# PIC32MZ2051W104132 register map
Vendor: Microchip
Registers are 32-bit, read-write, no defined reset value unless marked. A register's access mark holds for its fields unless they carry their own. Addresses are absolute, and some are shared; only a register's first bit layout is shown; [hi:lo] are bit positions; {n}, {i} and the like mark numbered series.

## SFR
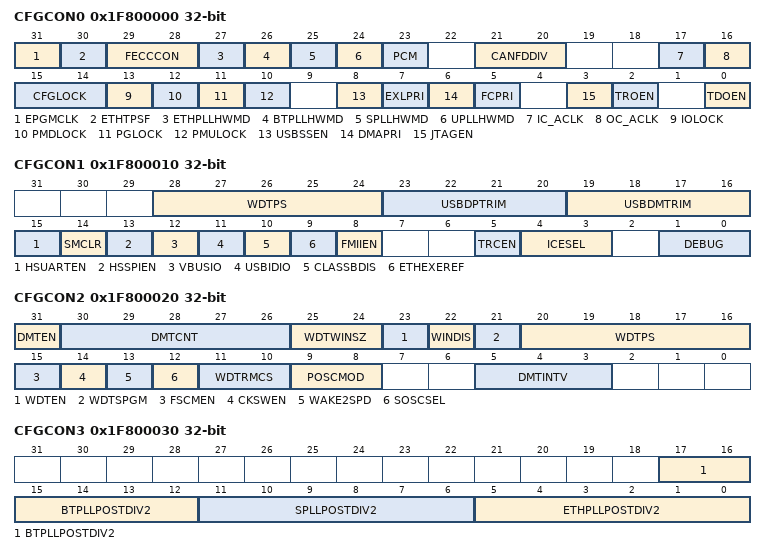
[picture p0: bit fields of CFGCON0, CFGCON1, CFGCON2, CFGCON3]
0x1F800000 CFGCON0 — (power-on value qqqqqqqqq-qq--qqqqqqqq-qqqq-qq-q)
  [31] EPGMCLK
  [30] ETHTPSF
  [29:28] FECCCON
  [27] ETHPLLHWMD
  [26] BTPLLHWMD
  [25] SPLLHWMD
  [24] UPLLHWMD
  [23] PCM
  [21:20] CANFDDIV — CAN-FD divider control
  [17] IC_ACLK
  [16] OC_ACLK
  [15:14] CFGLOCK
  [13] IOLOCK
  [12] PMDLOCK
  [11] PGLOCK
  [10] PMULOCK
  [8] USBSSEN
  [7] EXLPRI
  [6] DMAPRI
  [5] FCPRI
  [3] JTAGEN — JTAG control bit
  [2] TROEN — Trace clock control bit
  [0] TDOEN — TDO control for 2 wire JTAG protocol
0x1F800010 CFGCON1 — (power-on value ---qqqqqqqqqqqqqqqqqqqqq--qqq-qq)
  [28:24] WDTPS, [23:20] USBDPTRIM, [19:16] USBDMTRIM, [15] HSUARTEN, [14] SMCLR, [13] HSSPIEN, [12] VBUSIO, [11] USBIDIO, [10] CLASSBDIS, [9] ETHEXEREF, [8] FMIIEN, [5] TRCEN, [4:3] ICESEL, [1:0] DEBUG
0x1F800020 CFGCON2 — (power-on value qqqqqqqqqqqqqqqqqqqqqqqq--qqq---)
  [31] DMTEN, [30:26] DMTCNT, [25:24] WDTWINSZ, [23] WDTEN, [22] WINDIS, [21] WDTSPGM, [20:16] WDTPS, [15] FSCMEN, [14] CKSWEN, [13] WAKE2SPD, [12] SOSCSEL, [11:10] WDTRMCS, [9:8] POSCMOD, [5:3] DMTINTV
0x1F800030 CFGCON3 — (power-on value --------------qqqqqqqqqqqqqqqqqq)
  [17:12] BTPLLPOSTDIV2, [11:6] SPLLPOSTDIV2, [5:0] ETHPLLPOSTDIV2
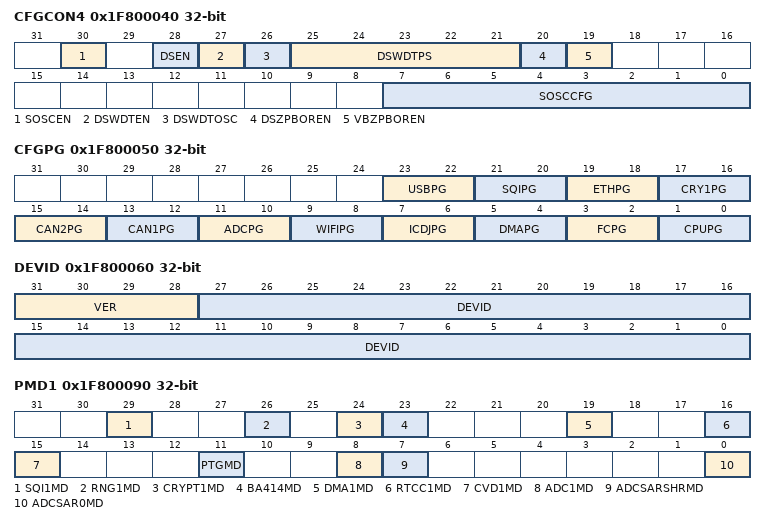
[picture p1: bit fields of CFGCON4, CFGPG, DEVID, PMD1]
0x1F800040 CFGCON4 — (power-on value -q-qqqqqqqqqq-----------qqqqqqqq)
  [30] SOSCEN, [28] DSEN, [27] DSWDTEN, [26] DSWDTOSC, [25:21] DSWDTPS, [20] DSZPBOREN, [19] VBZPBOREN, [7:0] SOSCCFG
0x1F800050 CFGPG — (power-on value --------qqqqqqqqqqqqqqqqqqqqqqqq)
  [23:22] USBPG, [21:20] SQIPG, [19:18] ETHPG, [17:16] CRY1PG, [15:14] CAN2PG, [13:12] CAN1PG, [11:10] ADCPG, [9:8] WIFIPG, [7:6] ICDJPG, [5:4] DMAPG, [3:2] FCPG, [1:0] CPUPG
0x1F800060 DEVID ro — (power-on value qqqqqqqqqqqqqqqqqqqqqqqqqqqqqqqq)
  [31:28] VER, [27:0] DEVID
0x1F800070 USERID — (power-on value ----------------xxxxxxxxxxxxxxxx)
  [15:0] USERID
0x1F800080 SYSKEY — (power-on value xxxxxxxxxxxxxxxxxxxxxxxxxxxxxxxx)
0x1F800090 PMD1 — (power-on value --x--x-xx---x--xx---x--xx------x)
  [29] SQI1MD, [26] RNG1MD, [24] CRYPT1MD, [23] BA414MD, [19] DMA1MD, [16] RTCC1MD, [15] CVD1MD, [11] PTGMD, [8] ADC1MD, [7] ADCSARSHRMD, [0] ADCSAR0MD
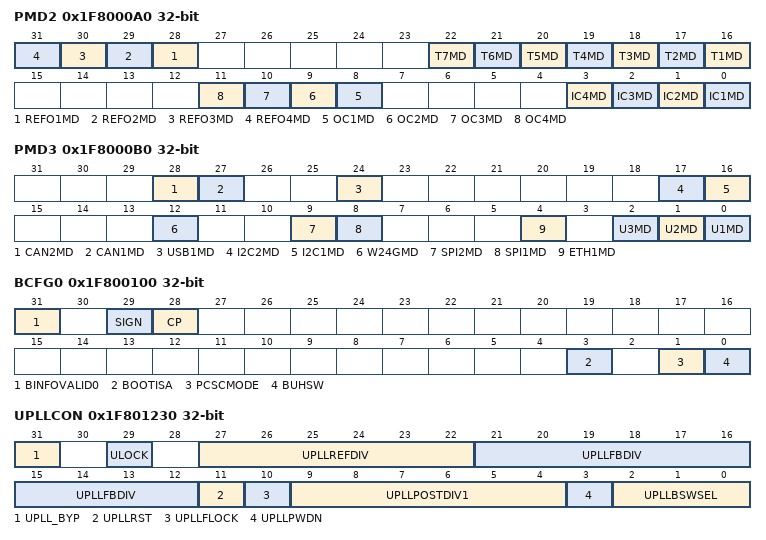
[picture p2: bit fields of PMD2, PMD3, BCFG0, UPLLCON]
0x1F8000A0 PMD2 — (power-on value xxxx-----xxxxxxx----xxxx----xxxx)
  [n+27] REFO{n}MD (n=1..4), [n+15] T{n}MD (n=1..7), [n+7] OC{n}MD (n=1..4), [n-1] IC{n}MD (n=1..4)
0x1F8000B0 PMD3 — (power-on value ---xx--x------xx---x--xx---x-xxx)
  [28] CAN2MD, [27] CAN1MD, [24] USB1MD, [17] I2C2MD, [16] I2C1MD, [12] W24GMD, [9] SPI2MD, [8] SPI1MD, [4] ETH1MD, [2] U3MD, [1] U2MD, [0] U1MD
0x1F800100 BCFG0 ro — (power-on value q-qq------------------------q-qq)
  [31] BINFOVALID0, [29] SIGN, [28] CP, [3] BOOTISA, [1] PCSCMODE, [0] BUHSW
0x1F801230 UPLLCON — (power-on value x-x-xxxxxxxxxxxxxxxxxxxxxxxxxxxx)
  [31] UPLL_BYP, [29] ULOCK, [27:22] UPLLREFDIV, [21:12] UPLLFBDIV, [11] UPLLRST, [10] UPLLFLOCK, [9:4] UPLLPOSTDIV1, [3] UPLLPWDN, [2:0] UPLLBSWSEL
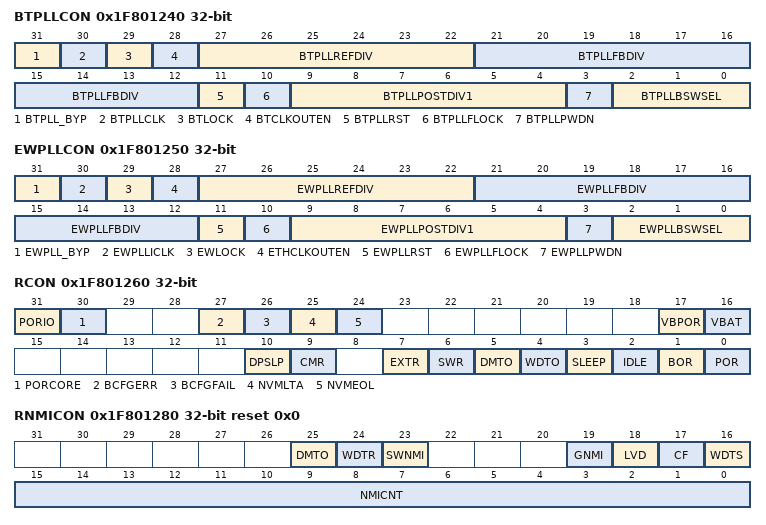
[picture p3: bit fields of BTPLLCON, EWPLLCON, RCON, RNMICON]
0x1F801240 BTPLLCON — (power-on value xxxxxxxxxxxxxxxxxxxxxxxxxxxxxxxx)
  [31] BTPLL_BYP, [30] BTPLLCLK, [29] BTLOCK, [28] BTCLKOUTEN, [27:22] BTPLLREFDIV, [21:12] BTPLLFBDIV, [11] BTPLLRST, [10] BTPLLFLOCK, [9:4] BTPLLPOSTDIV1, [3] BTPLLPWDN, [2:0] BTPLLBSWSEL
0x1F801250 EWPLLCON — (power-on value xxxxxxxxxxxxxxxxxxxxxxxxxxxxxxxx)
  [31] EWPLL_BYP, [30] EWPLLICLK, [29] EWLOCK, [28] ETHCLKOUTEN, [27:22] EWPLLREFDIV, [21:12] EWPLLFBDIV, [11] EWPLLRST, [10] EWPLLFLOCK, [9:4] EWPLLPOSTDIV1, [3] EWPLLPWDN, [2:0] EWPLLBSWSEL
0x1F801260 RCON — (power-on value 00--00x0-------------x0-00000011)
  [31] PORIO, [30] PORCORE, [27] BCFGERR, [26] BCFGFAIL, [25] NVMLTA, [24] NVMEOL, [17] VBPOR, [16] VBAT, [10] DPSLP, [9] CMR, [7] EXTR, [6] SWR, [5] DMTO, [4] WDTO, [3] SLEEP, [2] IDLE, [1] BOR, [0] POR
0x1F801270 RSWRST wo reset 0x0
  [0] SWRST
0x1F801280 RNMICON reset 0x0
  [25] DMTO, [24] WDTR, [23] SWNMI, [19] GNMI, [18] LVD, [17] CF, [16] WDTS, [15:0] NMICNT
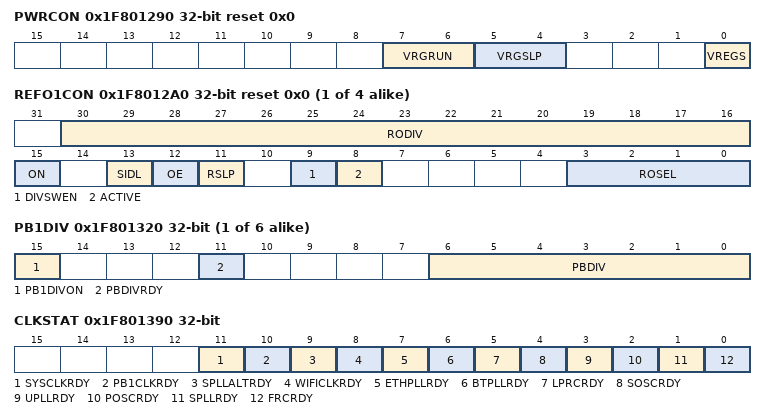
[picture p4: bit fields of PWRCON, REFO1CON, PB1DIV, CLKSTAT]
0x1F801290 PWRCON reset 0x0
  [7:6] VRGRUN, [5:4] VRGSLP, [0] VREGS
{0x1F801280+0x20*i} REFO{i}CON reset 0x0 (i=1..4)
  [30:16] RODIV, [15] ON, [13] SIDL, [12] OE, [11] RSLP, [9] DIVSWEN, [8] ACTIVE ro, [3:0] ROSEL
{0x1F801290+0x20*i} REFO{i}TRIM reset 0x0 (i=1..4)
  [31:23] ROTRIM
{0x1F801310+0x10*i} PB{i}DIV (i=1..6) — (power-on value ----------------1---1----xxxxxxx)
  [15] PB{i}DIVON, [11] PBDIVRDY ro, [6:0] PBDIV
0x1F801390 CLKSTAT — (power-on value --------------------xxxx0x0000x0)
  [11] SYSCLKRDY, [10] PB1CLKRDY, [9] SPLLALTRDY, [8] WIFICLKRDY, [7] ETHPLLRDY ro, [6] BTPLLRDY, [5] LPRCRDY ro, [4] SOSCRDY ro, [3] UPLLRDY ro, [2] POSCRDY ro, [1] SPLLRDY, [0] FRCRDY ro
0x1F8013A0 OSCCONBAR access not given
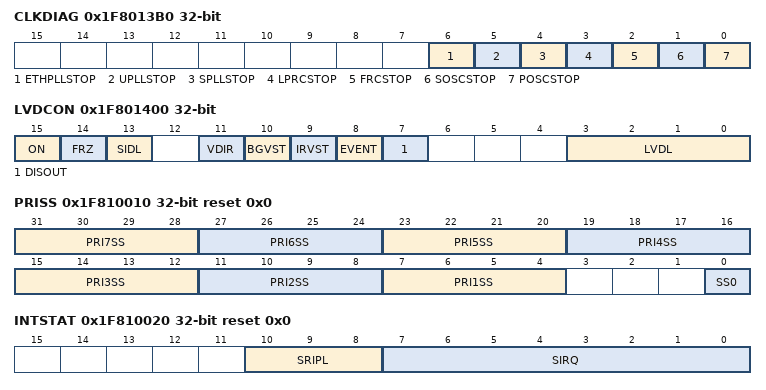
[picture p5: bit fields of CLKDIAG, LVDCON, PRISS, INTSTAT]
0x1F8013B0 CLKDIAG — (power-on value -------------------------xxxxxxx)
  [6] ETHPLLSTOP, [5] UPLLSTOP, [4] SPLLSTOP, [3] LPRCSTOP, [2] FRCSTOP, [1] SOSCSTOP, [0] POSCSTOP
0x1F801400 LVDCON — (power-on value ----------------xxx-xxxxx---xxxx)
  [15] ON, [14] FRZ, [13] SIDL, [11] VDIR, [10] BGVST, [9] IRVST, [8] EVENT, [7] DISOUT, [3:0] LVDL
{0x1F801800+4i} INT{i}R (i=0..4) — (power-on value ----------------------------xxxx)
  [3:0] INT{i}R
{0x1F801810+4i} T{i}CKR (i=1..7) — (power-on value ----------------------------xxxx)
  [3:0] T{i}CKR
{0x1F801834+4i} IC{i}R (i=1..4) — (power-on value ----------------------------xxxx)
  [3:0] IC{i}R
0x1F80185C OCFAR — (power-on value ----------------------------xxxx)
  [3:0] OCFAR
0x1F801860 OCFBR — (power-on value ----------------------------xxxx)
  [3:0] OCFBR
0x1F801864 OCFCR — (power-on value ----------------------------xxxx)
  [3:0] OCFCR
0x1F801868 OCFDR — (power-on value ----------------------------xxxx)
  [3:0] OCFDR
{0x1F801864+8i} U{i}RXR (i=1..3) — (power-on value ----------------------------xxxx)
  [3:0] U{i}RXR
{0x1F801868+8i} U{i}CTSR (i=1..3) — (power-on value ----------------------------xxxx)
  [3:0] U{i}CTSR
0x1F80188C PTG30R — (power-on value ----------------------------xxxx)
  [3:0] PTG30R
0x1F801890 PTG31R — (power-on value ----------------------------xxxx)
  [3:0] PTG31R
0x1F801898 SDI1R — (power-on value ----------------------------xxxx)
  [3:0] SDI1R
0x1F80189C SS1INR — (power-on value ----------------------------xxxx)
  [3:0] SS1INR
0x1F8018A4 SDI2R — (power-on value ----------------------------xxxx)
  [3:0] SDI2R
0x1F8018A8 SS2INR — (power-on value ----------------------------xxxx)
  [3:0] SS2INR
0x1F8018C4 C1RXR — (power-on value ----------------------------xxxx)
  [3:0] C1RXR
0x1F8018C8 C2RXR — (power-on value ----------------------------xxxx)
  [3:0] C2RXR
0x1F8018CC REFIR — (power-on value ----------------------------xxxx)
  [3:0] REFIR
0x1F801974 ECOLR — (power-on value ----------------------------xxxx)
  [3:0] ECOLR
0x1F801978 ECRSR — (power-on value ----------------------------xxxx)
  [3:0] ECRSR
0x1F80197C ETXCLKR — (power-on value ----------------------------xxxx)
  [3:0] ETXCLKR
0x1F801980 ERXD3R — (power-on value ----------------------------xxxx)
  [3:0] ERXD3R
0x1F801984 ERXD2R — (power-on value ----------------------------xxxx)
  [3:0] ERXD2R
{0x1F801A00+4i} RPA{i}R (i=0..5) — (power-on value ---------------------------xxxxx)
  [4:0] RPA{i}R
{0x1F801A00+4i} RPA{i}R (i=10..15) — (power-on value ---------------------------xxxxx)
  [4:0] RPA{i}R
{0x1F801A40+4i} RPB{i}R (i=0..14) — (power-on value ---------------------------xxxxx)
  [4:0] RPB{i}R
{0x1F801A80+4i} RPC{i}R (i=0..15) — (power-on value ---------------------------xxxxx)
  [4:0] RPC{i}R
{0x1F801AC0+4i} RPK{i}R (i=0..14) — (power-on value ---------------------------xxxxx)
  [4:0] RPK{i}R
0x1F810010 PRISS reset 0x0
  [4n+3:4n] PRI{n}SS (n=1..7), [0] SS0
0x1F810020 INTSTAT ro reset 0x0
  [10:8] SRIPL, [7:0] SIRQ
0x1F810030 IPTMR reset 0x0
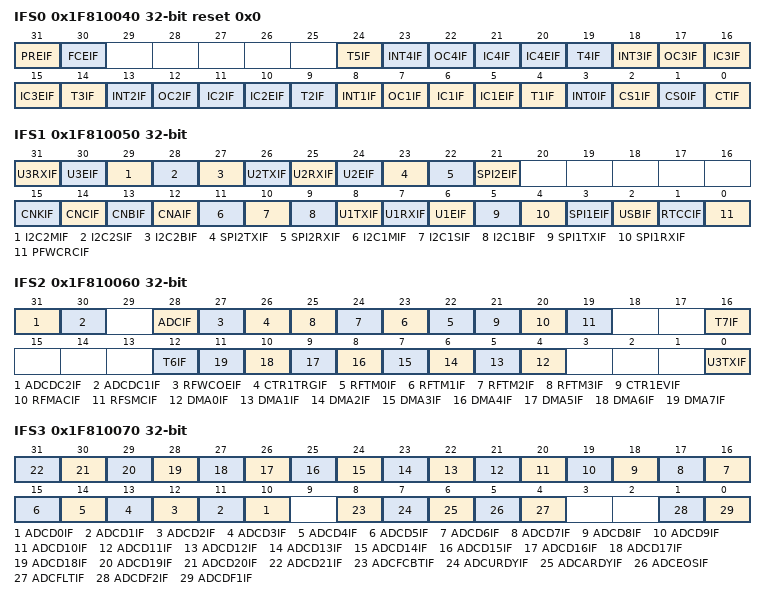
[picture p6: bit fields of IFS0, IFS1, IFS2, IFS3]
0x1F810040 IFS0 reset 0x0
  [31] PREIF, [30] FCEIF, [5n-1] T{n}IF (n=1..5), [5n+3] INT{n}IF (n=0..4), [5n+2] OC{n}IF (n=1..4), [5n+1] IC{n}IF (n=1..4), [5n] IC{n}EIF (n=1..4), [2] CS1IF, [1] CS0IF, [0] CTIF
0x1F810050 IFS1 — (power-on value xx000000000-----00000000000000x0)
  [31] U3RXIF, [30] U3EIF, [29] I2C2MIF, [28] I2C2SIF, [27] I2C2BIF, [26] U2TXIF, [25] U2RXIF, [24] U2EIF, [23] SPI2TXIF, [22] SPI2RXIF, [21] SPI2EIF, [15] CNKIF, [14] CNCIF, [13] CNBIF, [12] CNAIF, [11] I2C1MIF, [10] I2C1SIF, [9] I2C1BIF, [8] U1TXIF, [7] U1RXIF, [6] U1EIF, [5] SPI1TXIF, [4] SPI1RXIF, [3] SPI1EIF, [2] USBIF, [1] RTCCIF, [0] PFWCRCIF
0x1F810060 IFS2 — (power-on value 000000000000x000---000000000---x)
  [31] ADCDC2IF, [30] ADCDC1IF, [28] ADCIF, [27] RFWCOEIF, [26] CTR1TRGIF, [n+22] RFTM{n}IF (n=0..3), [21] CTR1EVIF, [20] RFMACIF, [19] RFSMCIF, [16] T7IF, [12] T6IF, [n+4] DMA{n}IF (n=0..7), [0] U3TXIF
0x1F810070 IFS3 — (power-on value xx00000000000000000-000000000000)
  [n+10] ADCD{n}IF (n=0..21), [8] ADCFCBTIF, [7] ADCURDYIF, [6] ADCARDYIF, [5] ADCEOSIF, [4] ADCFLTIF, [1] ADCDF2IF, [0] ADCDF1IF
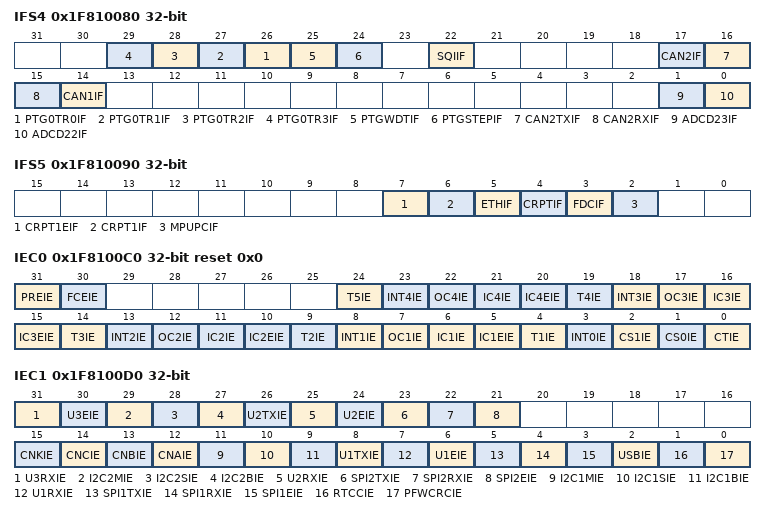
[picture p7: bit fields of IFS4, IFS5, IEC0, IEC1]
0x1F810080 IFS4 — (power-on value 00000000000000xxx0000000000000xx)
  [n+26] PTG0TR{n}IF (n=0..3), [25] PTGWDTIF, [24] PTGSTEPIF, [22] SQIIF, [17] CAN2IF, [16] CAN2TXIF, [15] CAN2RXIF, [14] CAN1IF, [1] ADCD23IF, [0] ADCD22IF
0x1F810090 IFS5 — (power-on value -00000000000000000000000xxxx0000)
  [7] CRPT1EIF, [6] CRPT1IF, [5] ETHIF, [4] CRPTIF, [3] FDCIF, [2] MPUPCIF
0x1F8100C0 IEC0 reset 0x0
  [31] PREIE, [30] FCEIE, [5n-1] T{n}IE (n=1..5), [5n+3] INT{n}IE (n=0..4), [5n+2] OC{n}IE (n=1..4), [5n+1] IC{n}IE (n=1..4), [5n] IC{n}EIE (n=1..4), [2] CS1IE, [1] CS0IE, [0] CTIE
0x1F8100D0 IEC1 — (power-on value xx000x000000000000000000000000x0)
  [31] U3RXIE, [30] U3EIE, [29] I2C2MIE, [28] I2C2SIE, [27] I2C2BIE, [26] U2TXIE, [25] U2RXIE, [24] U2EIE, [23] SPI2TXIE, [22] SPI2RXIE, [21] SPI2EIE, [15] CNKIE, [14] CNCIE, [13] CNBIE, [12] CNAIE, [11] I2C1MIE, [10] I2C1SIE, [9] I2C1BIE, [8] U1TXIE, [7] U1RXIE, [6] U1EIE, [5] SPI1TXIE, [4] SPI1RXIE, [3] SPI1EIE, [2] USBIE, [1] RTCCIE, [0] PFWCRCIE
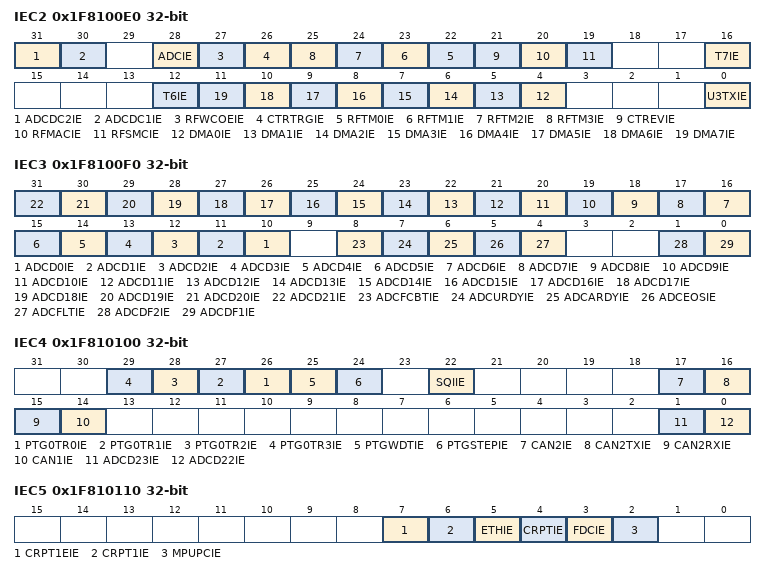
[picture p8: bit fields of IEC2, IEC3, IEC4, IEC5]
0x1F8100E0 IEC2 — (power-on value 000000000000x000000000000000000x)
  [31] ADCDC2IE, [30] ADCDC1IE, [28] ADCIE, [27] RFWCOEIE, [26] CTRTRGIE, [n+22] RFTM{n}IE (n=0..3), [21] CTREVIE, [20] RFMACIE, [19] RFSMCIE, [16] T7IE, [12] T6IE, [n+4] DMA{n}IE (n=0..7), [0] U3TXIE
0x1F8100F0 IEC3 — (power-on value xx00000000000000000-000000000000)
  [n+10] ADCD{n}IE (n=0..21), [8] ADCFCBTIE, [7] ADCURDYIE, [6] ADCARDYIE, [5] ADCEOSIE, [4] ADCFLTIE, [1] ADCDF2IE, [0] ADCDF1IE
0x1F810100 IEC4 — (power-on value 00000000000000xxx0000000000000xx)
  [n+26] PTG0TR{n}IE (n=0..3), [25] PTGWDTIE, [24] PTGSTEPIE, [22] SQIIE, [17] CAN2IE, [16] CAN2TXIE, [15] CAN2RXIE, [14] CAN1IE, [1] ADCD23IE, [0] ADCD22IE
0x1F810110 IEC5 — (power-on value -00000000000000000000000xxxx0000)
  [7] CRPT1EIE, [6] CRPT1IE, [5] ETHIE, [4] CRPTIE, [3] FDCIE, [2] MPUPCIE
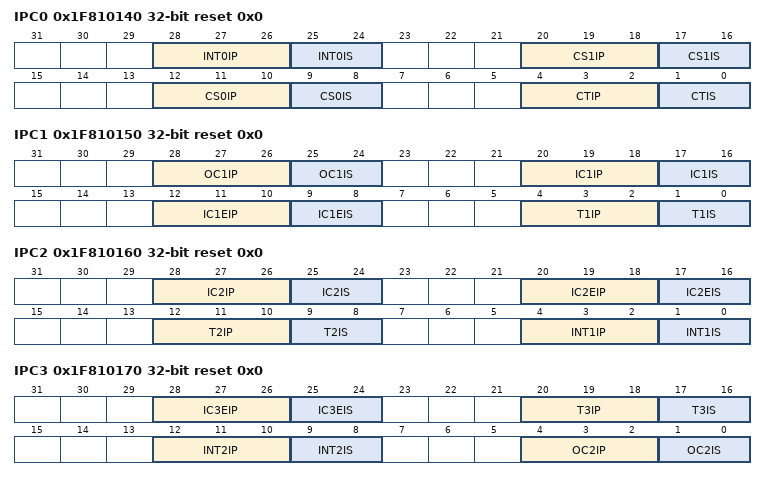
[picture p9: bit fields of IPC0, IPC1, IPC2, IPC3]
0x1F810140 IPC0 reset 0x0
  [28:26] INT0IP, [25:24] INT0IS, [20:18] CS1IP, [17:16] CS1IS, [12:10] CS0IP, [9:8] CS0IS, [4:2] CTIP, [1:0] CTIS
0x1F810150 IPC1 reset 0x0
  [28:26] OC1IP, [25:24] OC1IS, [20:18] IC1IP, [17:16] IC1IS, [12:10] IC1EIP, [9:8] IC1EIS, [4:2] T1IP, [1:0] T1IS
0x1F810160 IPC2 reset 0x0
  [28:26] IC2IP, [25:24] IC2IS, [20:18] IC2EIP, [17:16] IC2EIS, [12:10] T2IP, [9:8] T2IS, [4:2] INT1IP, [1:0] INT1IS
0x1F810170 IPC3 reset 0x0
  [28:26] IC3EIP, [25:24] IC3EIS, [20:18] T3IP, [17:16] T3IS, [12:10] INT2IP, [9:8] INT2IS, [4:2] OC2IP, [1:0] OC2IS
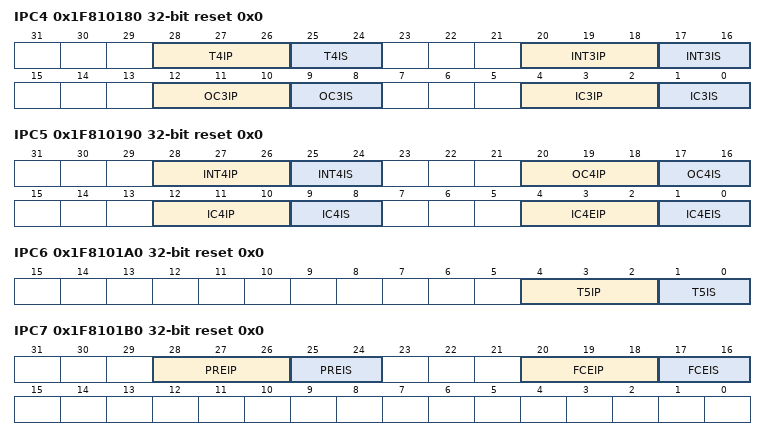
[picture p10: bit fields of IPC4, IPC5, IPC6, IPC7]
0x1F810180 IPC4 reset 0x0
  [28:26] T4IP, [25:24] T4IS, [20:18] INT3IP, [17:16] INT3IS, [12:10] OC3IP, [9:8] OC3IS, [4:2] IC3IP, [1:0] IC3IS
0x1F810190 IPC5 reset 0x0
  [28:26] INT4IP, [25:24] INT4IS, [20:18] OC4IP, [17:16] OC4IS, [12:10] IC4IP, [9:8] IC4IS, [4:2] IC4EIP, [1:0] IC4EIS
0x1F8101A0 IPC6 reset 0x0
  [4:2] T5IP, [1:0] T5IS
0x1F8101B0 IPC7 reset 0x0
  [28:26] PREIP, [25:24] PREIS, [20:18] FCEIP, [17:16] FCEIS
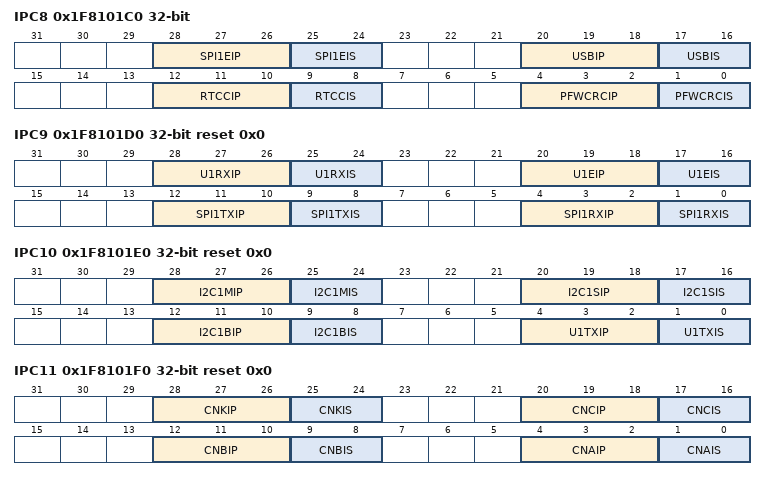
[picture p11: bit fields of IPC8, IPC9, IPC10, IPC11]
0x1F8101C0 IPC8 — (power-on value ---00000---00000---00000---xxxxx)
  [28:26] SPI1EIP, [25:24] SPI1EIS, [20:18] USBIP, [17:16] USBIS, [12:10] RTCCIP, [9:8] RTCCIS, [4:2] PFWCRCIP, [1:0] PFWCRCIS
0x1F8101D0 IPC9 reset 0x0
  [28:26] U1RXIP, [25:24] U1RXIS, [20:18] U1EIP, [17:16] U1EIS, [12:10] SPI1TXIP, [9:8] SPI1TXIS, [4:2] SPI1RXIP, [1:0] SPI1RXIS
0x1F8101E0 IPC10 reset 0x0
  [28:26] I2C1MIP, [25:24] I2C1MIS, [20:18] I2C1SIP, [17:16] I2C1SIS, [12:10] I2C1BIP, [9:8] I2C1BIS, [4:2] U1TXIP, [1:0] U1TXIS
0x1F8101F0 IPC11 reset 0x0
  [28:26] CNKIP, [25:24] CNKIS, [20:18] CNCIP, [17:16] CNCIS, [12:10] CNBIP, [9:8] CNBIS, [4:2] CNAIP, [1:0] CNAIS
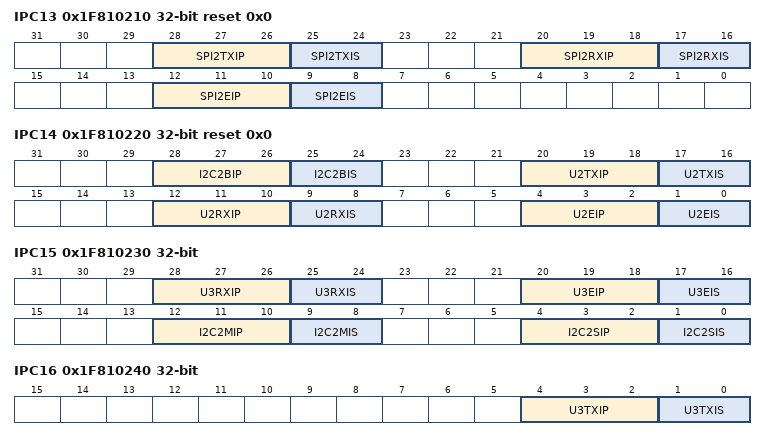
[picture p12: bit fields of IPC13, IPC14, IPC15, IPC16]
0x1F810210 IPC13 reset 0x0
  [28:26] SPI2TXIP, [25:24] SPI2TXIS, [20:18] SPI2RXIP, [17:16] SPI2RXIS, [12:10] SPI2EIP, [9:8] SPI2EIS
0x1F810220 IPC14 reset 0x0
  [28:26] I2C2BIP, [25:24] I2C2BIS, [20:18] U2TXIP, [17:16] U2TXIS, [12:10] U2RXIP, [9:8] U2RXIS, [4:2] U2EIP, [1:0] U2EIS
0x1F810230 IPC15 — (power-on value ---xxxxx---xxxxx---00000---00000)
  [28:26] U3RXIP, [25:24] U3RXIS, [20:18] U3EIP, [17:16] U3EIS, [12:10] I2C2MIP, [9:8] I2C2MIS, [4:2] I2C2SIP, [1:0] I2C2SIS
0x1F810240 IPC16 — (power-on value ---------------------------xxxxx)
  [4:2] U3TXIP, [1:0] U3TXIS
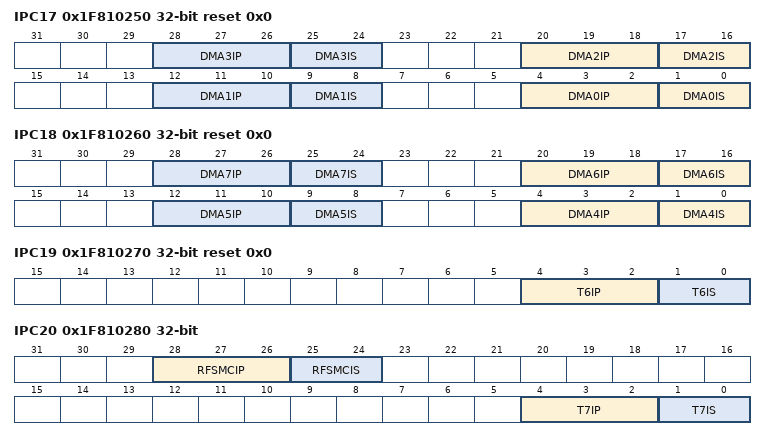
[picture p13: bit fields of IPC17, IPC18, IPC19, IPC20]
0x1F810250 IPC17 reset 0x0
  [8n+4:8n+2] DMA{n}IP (n=0..3), [8n+1:8n] DMA{n}IS (n=0..3)
0x1F810260 IPC18 reset 0x0
  [8n-28:8n-30] DMA{n}IP (n=4..7), [8n-31:8n-32] DMA{n}IS (n=4..7)
0x1F810270 IPC19 reset 0x0
  [4:2] T6IP, [1:0] T6IS
0x1F810280 IPC20 — (power-on value ---xxxxx-------------------00000)
  [28:26] RFSMCIP, [25:24] RFSMCIS, [4:2] T7IP, [1:0] T7IS
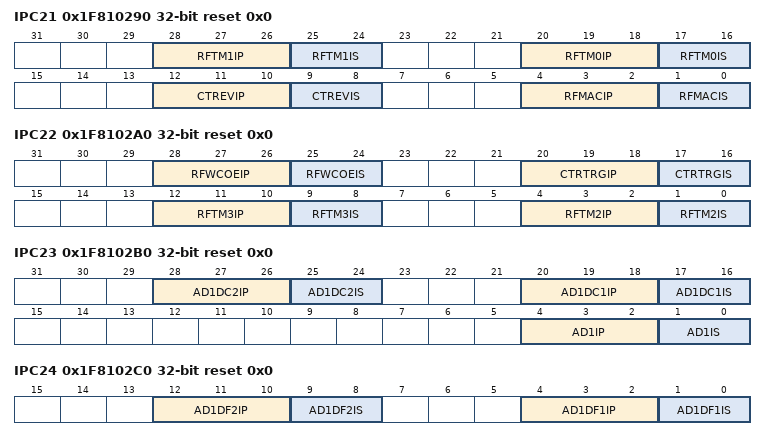
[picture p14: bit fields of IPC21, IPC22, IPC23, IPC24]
0x1F810290 IPC21 reset 0x0
  [28:26] RFTM1IP, [25:24] RFTM1IS, [20:18] RFTM0IP, [17:16] RFTM0IS, [12:10] CTREVIP, [9:8] CTREVIS, [4:2] RFMACIP, [1:0] RFMACIS
0x1F8102A0 IPC22 reset 0x0
  [28:26] RFWCOEIP, [25:24] RFWCOEIS, [20:18] CTRTRGIP, [17:16] CTRTRGIS, [12:10] RFTM3IP, [9:8] RFTM3IS, [4:2] RFTM2IP, [1:0] RFTM2IS
0x1F8102B0 IPC23 reset 0x0
  [28:26] AD1DC2IP, [25:24] AD1DC2IS, [20:18] AD1DC1IP, [17:16] AD1DC1IS, [4:2] AD1IP, [1:0] AD1IS
0x1F8102C0 IPC24 reset 0x0
  [12:10] AD1DF2IP, [9:8] AD1DF2IS, [4:2] AD1DF1IP, [1:0] AD1DF1IS
0x1F8102D0 IPC25 reset 0x0
  [28:26] AD1RSIP, [25:24] AD1RSIS, [20:18] AD1ARIP, [17:16] AD1ARIS, [12:10] AD1EOSIP, [9:8] AD1EOSIS, [4:2] AD1DFIIP, [1:0] AD1DFIIS
0x1F8102E0 IPC26 reset 0x0
  [28:26] AD1I01IP, [25:24] AD1I01IS, [20:18] AD1I00IP, [17:16] AD1I00IS, [4:2] AD1FCIP, [1:0] AD1FCIS
0x1F8102F0 IPC27 — (power-on value ---00000---00000---00000---xxxxx)
  [8n-12:8n-14] AD1I{n:02}IP (n=2..5), [8n-15:8n-16] AD1I{n:02}IS (n=2..5)
0x1F810300 IPC28 reset 0x0
  [8n-44:8n-46] AD1I{n:02}IP (n=6..9), [8n-47:8n-48] AD1I{n:02}IS (n=6..9)
0x1F810310 IPC29 reset 0x0
  [8n-76:8n-78] AD1I{n}IP (n=10..13), [8n-79:8n-80] AD1I{n}IS (n=10..13)
0x1F810320 IPC30 reset 0x0
  [8n-108:8n-110] AD1I{n}IP (n=14..17), [8n-111:8n-112] AD1I{n}IS (n=14..17)
0x1F810330 IPC31 — (power-on value ---xxxxx---xxxxx---00000---00000)
  [8n-140:8n-142] AD1I{n}IP (n=18..21), [8n-143:8n-144] AD1I{n}IS (n=18..21)
0x1F810340 IPC32 — (power-on value -------------------xxxxx---xxxxx)
  [12:10] AD1I23IP, [9:8] AD1I23IS, [4:2] AD1I22IP, [1:0] AD1I22IS
0x1F810370 IPC35 — (power-on value ---xxxxx---00000----------------)
  [28:26] CAN2RXIP, [25:24] CAN2RXIS, [20:18] CAN1IP, [17:16] CAN1IS
0x1F810380 IPC36 — (power-on value -------------------xxxxx---xxxxx)
  [12:10] CAN2IP, [9:8] CAN2IS, [4:2] CAN2TXIP, [1:0] CAN2TXIS
0x1F810390 IPC37 reset 0x0
  [20:18] SQIIP, [17:16] SQIIS
0x1F8103A0 IPC38 reset 0x0
  [28:26] PTGTR1IP, [25:24] PTGTR1IS, [20:18] PTGTR0IP, [17:16] PTGTR0IS, [12:10] PTGWDTIP, [9:8] PTGWDTIS, [4:2] PTGSTEPIP, [1:0] PTGSTEPIS
0x1F8103B0 IPC39 reset 0x0
  [12:10] PTGTR3IP, [9:8] PTGTR3IS, [4:2] PTGTR2IP, [1:0] PTGTR2IS
0x1F8103C0 IPC40 reset 0x0
  [28:26] FDCIP, [25:24] FDCIS, [20:18] MPUPCIP, [17:16] MPUPCIS
0x1F8103D0 IPC41 — (power-on value ---xxxxx---xxxxx---xxxxx---xxxxx)
  [28:26] CRPT1EIP, [25:24] CRPT1EIS, [20:18] CRPT1IP, [17:16] CRPT1IS, [12:10] ETHIP, [9:8] ETHIS, [4:2] CRPTIP, [1:0] CRPTIS
0x1F8103E0 IPC42 — (power-on value ---------------------------xxxxx)
  [4:2] CVDIP, [1:0] CVDIS
0x1F813E00 PMUSPICTRL — (power-on value xx-----xxxxxxxxxxxxxxxxxxxxxxxxx)
  [31] SPIRST, [30] PMUCRST, [24] CMD, [23:16] SPIADDR, [15:0] SPIWDATA
0x1F813E04 PMUSPISTAT — (power-on value xxxxxxxxxxxxxxxxxxxxxxxxx------x)
  [31:16] SPIRDATA, [15:8] SPIRADDR, [7] SPIRDY, [0] SPIERR
0x1F813E08 PMUCLKCTRL — (power-on value xxxxxx-xxxxxxxxxxxxxxxxxxxxxxxxx)
  [31] WCMRET, [30] WLDOOFF, [29] FBCLKCFG, [28] BUCKBOREN, [27] ADCBOREN, [26] MDLOEXTBOREN, [24] BKCLKHWOVR, [23:20] CMPCYCLE, [19] WCMRETEXBCWD, [18] MVREFFSMEN, [17] MLDOEXTEN, [16] BACWD, [15:14] BUCKSRC, [13:8] BUCKCLKDIV, [7] SPISRC, [6] PMUANABUCKBOREN, [5:0] SPICLKDIV
{0x1F813E08+4i} PMUMODECTRL{i} (i=1..4) — (power-on value xxxxxxxx---xxxxx---xxxxx---xxxxx)
  [31] BUCKEN, [30] MLDOEN, [29] BUCKMODE, [36-8n:32-8n] VREG{n}CTRL (n=1..4)
0x1F813E1C PMUOVERCTRL — (power-on value 1000000001-00000xx-00000---00000)
  [31] OBUCKEN, [30] OMLDOEN, [29] OBUCKMODE, [36-8n:32-8n] VREG{n}OCTRL (n=1..4), [23] OVEREN, [22] PHWC, [15] OWLDOEN, [14] ORETEXIT
0x1F813E20 PMUCMODE — (power-on value 01000000xxx00000---00000---00000)
  [31] CBUCKEN ro, [30] CMLDOEN ro, [29] CBUCKMODE ro, [36-8n:32-8n] CVREG{n}OCTRL ro (n=1..4), [23] MLDOEXTBOR, [22] BUCKBOR, [21] ADCBOR
0x1F813E24 PMUSTATUS — (power-on value 000000000000000000000000xx000000)
  [31] BSSERR ro, [30:24] BSSENUM ro, [23:8] BSSEDATA ro, [7] WLDORDY, [6] PMUANABUCKBOR, [5] WCMRM ro, [4:0] STATUS ro
{0x1F813E24+4i} PMUSEQ{i} ro (i=1..3) — (power-on value qqqqqqqqqqqqqqqqqqqqqqqqqqqqqqqq)
  [31:16] SPIDATA, [15:8] SPIADDR, [7] CMD, [6] CMPBVAL, [5:0] DELAY
0x1F813E34 PMUSEQ4 — (power-on value xxxxxxxxxxxxxxxxxxxxxxxxxxxxxxxx)
  [31:16] SPIDATA, [15:8] SPIADDR, [7] CMD, [6] CMPBVAL, [5:0] DELAY
0x1F813E38 PMUCFG — (power-on value xxxxxxxxxxxxxxxxxxxxxxxxxxxxxxxx)
  [31:28] ADCCPH, [27:24] ADCCPL, [23:20] BUCKCPH, [19:16] BUCKCPL, [15:14] MLDOEXTL, [13:7] MLDOSWDELAY, [6:0] BUCKSWDELAY
0x1F813E3C PMUWCMCMD — (power-on value xx-x---------xxx-----xxxxxxxxxxx)
  [31] MODE, [30] CMD, [28] WCMRDY ro, [18:16] WCMCLKDIV, [10:0] WCMADDR
0x1F813E40 PMUWCMWDATA — (power-on value xxxxxxxxxxxxxxxxxxxxxxxxxxxxxxxx)
  [31:0] WDATA
0x1F813E44 PMUWCMRDATA — (power-on value xxxxxxxxxxxxxxxxxxxxxxxxxxxxxxxx)
  [31:0] RDATA
0x1F813E48 PMUVBCCMD — (power-on value -x-x------------xxxxxxxxxxxxxxxx)
  [30] CMD, [28] VBCRDY, [15:0] VBCADDR
0x1F813E4C PMUVCBWDATA — (power-on value xxxxxxxxxxxxxxxxxxxxxxxxxxxxxxxx)
  [31:0] WDATA
0x1F813E50 PMUVCBRDATA — (power-on value xxxxxxxxxxxxxxxxxxxxxxxxxxxxxxxx)
  [31:0] RDATA
0x1F813E54 WCMCFG — (power-on value -xxx-xxx-xxx-xxx-xxx-xxx-xxx-xxx)
  [4n+6:4n+4] SRAM{n}CFG (n=1..6), [6:4] WCM2CFG, [2:0] WCM1CFG
0x1F813E58 PMUIENB — (power-on value ---------------------------xxxxx)
  [4] VBCIAIEN, [3] WCMIAIEN, [2] SCMPIEN, [1] BUCKBORIEN, [0] ADCBORIEN
0x1F813E5C PMUISTAT — (power-on value ---------------------------xxxxx)
  [4] VBCIAINT, [3] WCMIAINT, [2] SCMPINT, [1] BUCKBORINT, [0] ADCBORINT
0x1F813E60 WCMSIZ — (power-on value --xx--xx--xx--xx--xx--xx--xx--xx)
  [4n+5:4n+4] SRAM{n}SIZ (n=1..6), [5:4] WCM2SIZ, [1:0] WCM1SIZ
0x1F814000 PMUWCM — (power-on value xxxxxxxxxxxxxxxxxxxxxxxxxxxxxxxx)
  [31:0] WCMDATA
0x1F871000 DSCON — (power-on value ----------------x-xx---x------xx)
  [15] DSEN, [13] DSGPREN, [12] RTCDIS, [8] RTCCWDIS, [1] DSBOR, [0] RELEASE
0x1F871004 DSWAKE — (power-on value -----------------------xx-xxxxx-)
  [8] DSINT0, [7] DSFLT, [5] EXT, [4] DSWDT, [3] DSRTC, [2] DSMCLR, [1] ICD
0x1F871008 DSGPR0 — (power-on value xxxxxxxxxxxxxxxxxxxxxxxxxxxxxxxx)
  [31:0] DSGPR
{0x1F87100C+4i} DSGPR{i} (i=1..32) — (power-on value xxxxxxxxxxxxxxxxxxxxxxxxxxxxxxxx)
  [31:0] DSGPR
0x1F8E4060 CEREV — (power-on value --------xxxxxxxxxxxxxxxxxxxxxxxx)
  [23:16] MAINTENANCE, [15:8] MINOR, [7:0] MAJOR
0x1F920000 PKCONFIG — (power-on value -----------xxxxx---xxxxx---xxxxx)
  [20:16] OPPTRC, [12:8] OPPTRB, [4:0] OPPTRA
0x1F920004 PKCOMMAND — (power-on value xxx-------------xxxxxxxxxxxxxxxx)
  [31] CALCR2, [30] SIGNB, [29] SIGNA, [15:8] OPSIZE, [7] FIELD, [6:0] OPERATION
0x1F920008 PKCONTROL — (power-on value -------------------------------x)
  [0] START
0x1F92000C PKSTATUS — (power-on value ---------------x---xxxx-xxxxxxxx)
  [16] BUSY, [12] PRIME ro, [11] NONINV ro, [10] PABINVAL ro, [9] SIGINVAL ro, [7] PNINVAL ro, [6] CPLINVAL ro, [5] PXINF ro, [4] PXNOC ro, [3:0] EADDR ro
0x1F920010 PKVERSION — (power-on value ----------------xxxxxxxxxxxxxxxx)
  [15:8] HWVER, [7:0] SWVER
